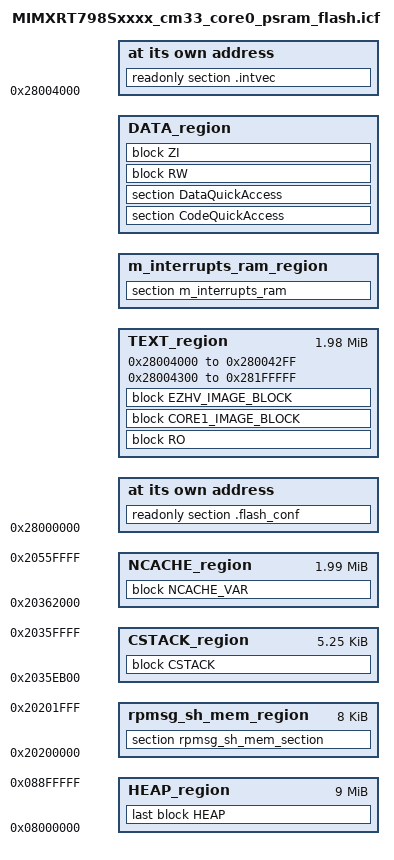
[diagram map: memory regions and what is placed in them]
/*
** ###################################################################
**     Processors:          MIMXRT798SGAWAR_cm33_core0
**                          MIMXRT798SGFOA_cm33_core0
**
**     Compiler:            IAR ANSI C/C++ Compiler for ARM
**     Reference manual:    iMXRT700RM Rev.2 DraftA, 05/2024
**     Version:             rev. 2.0, 2024-05-28
**     Build:               b240528
**
**     Abstract:
**         Linker file for the IAR ANSI C/C++ Compiler for ARM
**
**     Copyright 2024 NXP
**     SPDX-License-Identifier: BSD-3-Clause
**
**     http:                 www.nxp.com
**     mail:                 support@nxp.com
**
** ###################################################################
*/

/* Stack and Heap Sizes */
define symbol __size_cstack__        = 0x1500;
define symbol __size_heap__          = 0x900000;

/* The SRAM region [0x000000-0x013FFF] is reserved for ROM bootloader execution. Can be reused after boot. */
/* The SRAM region [0x014000-0x07FFFF] is reserved for Non-cached shared memory or application data. */
/* The SRAM region [0x080000-0x77FFFF] is reserved for CPU0 application, last 5.5MB non-cacheable data for NPU/GPU/Display etc. */

define symbol __ram_vector_table_size__        =  isdefinedsymbol(__ram_vector_table__) ? 0x00000300 : 0;
define symbol __ram_vector_table_offset__      =  isdefinedsymbol(__ram_vector_table__) ? 0x000002FF : 0;

define symbol m_interrupts_start               = 0x28004000;
define symbol m_interrupts_end                 = 0x280042FF;

define symbol m_text_start                     = 0x28004300;
define symbol m_text_end                       = 0x281FFFFF;

define symbol m_interrupts_ram_start           = 0x20080000;
define symbol m_interrupts_ram_end             = 0x20080000 + __ram_vector_table_offset__;

define symbol m_data_start                     = m_interrupts_ram_start + __ram_vector_table_size__;
define symbol m_data_end                       = 0x2035FFFF;

define symbol m_heap_start                     = 0x08000000;
define symbol m_heap_end                       = 0x088FFFFF;

if (isdefinedsymbol(__use_shmem__)) {
  define exported symbol rpmsg_sh_mem_start      = 0x20200000;
  define exported symbol rpmsg_sh_mem_end        = 0x20201FFF;
  define symbol m_ncache_start                   = 0x20362000;
  define symbol m_ncache_end                     = 0x2055FFFF;
  define exported symbol __NCACHE_REGION_START   = m_ncache_start;
  define exported symbol __NCACHE_REGION_SIZE    = m_ncache_end - __NCACHE_REGION_START + 1;
}
else
{
  define symbol m_ncache_start                   = 0x20360000;
  define symbol m_ncache_end                     = 0x2055FFFF;
  define exported symbol __NCACHE_REGION_START   = m_ncache_start;
  define exported symbol __NCACHE_REGION_SIZE    = m_ncache_end - __NCACHE_REGION_START + 1;
}

define symbol m_core1_image_maximum_size       = 0x00080000;
define symbol m_ezhv_image_maximum_size        = 0x00008000;

define symbol m_boot_flash_conf_start          = 0x28000000;

define exported symbol __VECTOR_TABLE          = m_interrupts_start;
define exported symbol __VECTOR_RAM            = isdefinedsymbol(__ram_vector_table__) ? m_interrupts_ram_start : m_interrupts_start;
define exported symbol __RAM_VECTOR_TABLE_SIZE = __ram_vector_table_size__;

define memory mem with size = 4G;

define region TEXT_region             = mem:[from m_interrupts_start to m_interrupts_end]
                                      | mem:[from m_text_start to m_text_end];
define region m_interrupts_ram_region = mem:[from m_interrupts_ram_start to m_interrupts_ram_end];
define region DATA_region             = mem:[from m_data_start to m_data_end - __size_cstack__];
define region CSTACK_region           = mem:[from m_data_end-__size_cstack__ + 1 to m_data_end];
define region NCACHE_region           = mem:[from m_ncache_start to m_ncache_end];
define region HEAP_region             = mem:[from m_heap_start to m_heap_end];
if (isdefinedsymbol(__use_shmem__)) {
  define region rpmsg_sh_mem_region     = mem:[from rpmsg_sh_mem_start to rpmsg_sh_mem_end];
}

define block CSTACK    with alignment = 8, size = __size_cstack__   { };
define block HEAP      with alignment = 8, size = __size_heap__     { };
define block RO        { readonly };
define block RW        { readwrite };
define block ZI        { zi };
define block NCACHE_VAR    { section NonCacheable , section NonCacheable.init };
define block CORE1_IMAGE_BLOCK  with alignment = 16, maximum size = m_core1_image_maximum_size  { section  __core1_image };
define block EZHV_IMAGE_BLOCK  with alignment = 16, maximum size =m_ezhv_image_maximum_size   { section  __ezhv_image };

initialize by copy { readwrite, section .textrw , section CodeQuickAccess, section DataQuickAccess };

do not initialize  { section .noinit };
if (isdefinedsymbol(__use_shmem__)) {
  do not initialize  { section rpmsg_sh_mem_section };
}

keep{section .flash_conf };
place at address mem: m_boot_flash_conf_start    { readonly section .flash_conf };
place at address mem: m_interrupts_start    { readonly section .intvec };
place in TEXT_region                        { block RO };
place in TEXT_region                        { block CORE1_IMAGE_BLOCK };
place in TEXT_region                        { block EZHV_IMAGE_BLOCK };
place in m_interrupts_ram_region            { section m_interrupts_ram };
place in DATA_region                        { section CodeQuickAccess, section DataQuickAccess };
place in DATA_region                        { block RW };
place in DATA_region                        { block ZI };
place in HEAP_region                        { last block HEAP };
place in NCACHE_region                      { block NCACHE_VAR };
place in CSTACK_region                      { block CSTACK };
if (isdefinedsymbol(__use_shmem__)) {
  place in rpmsg_sh_mem_region                { section rpmsg_sh_mem_section };
}
